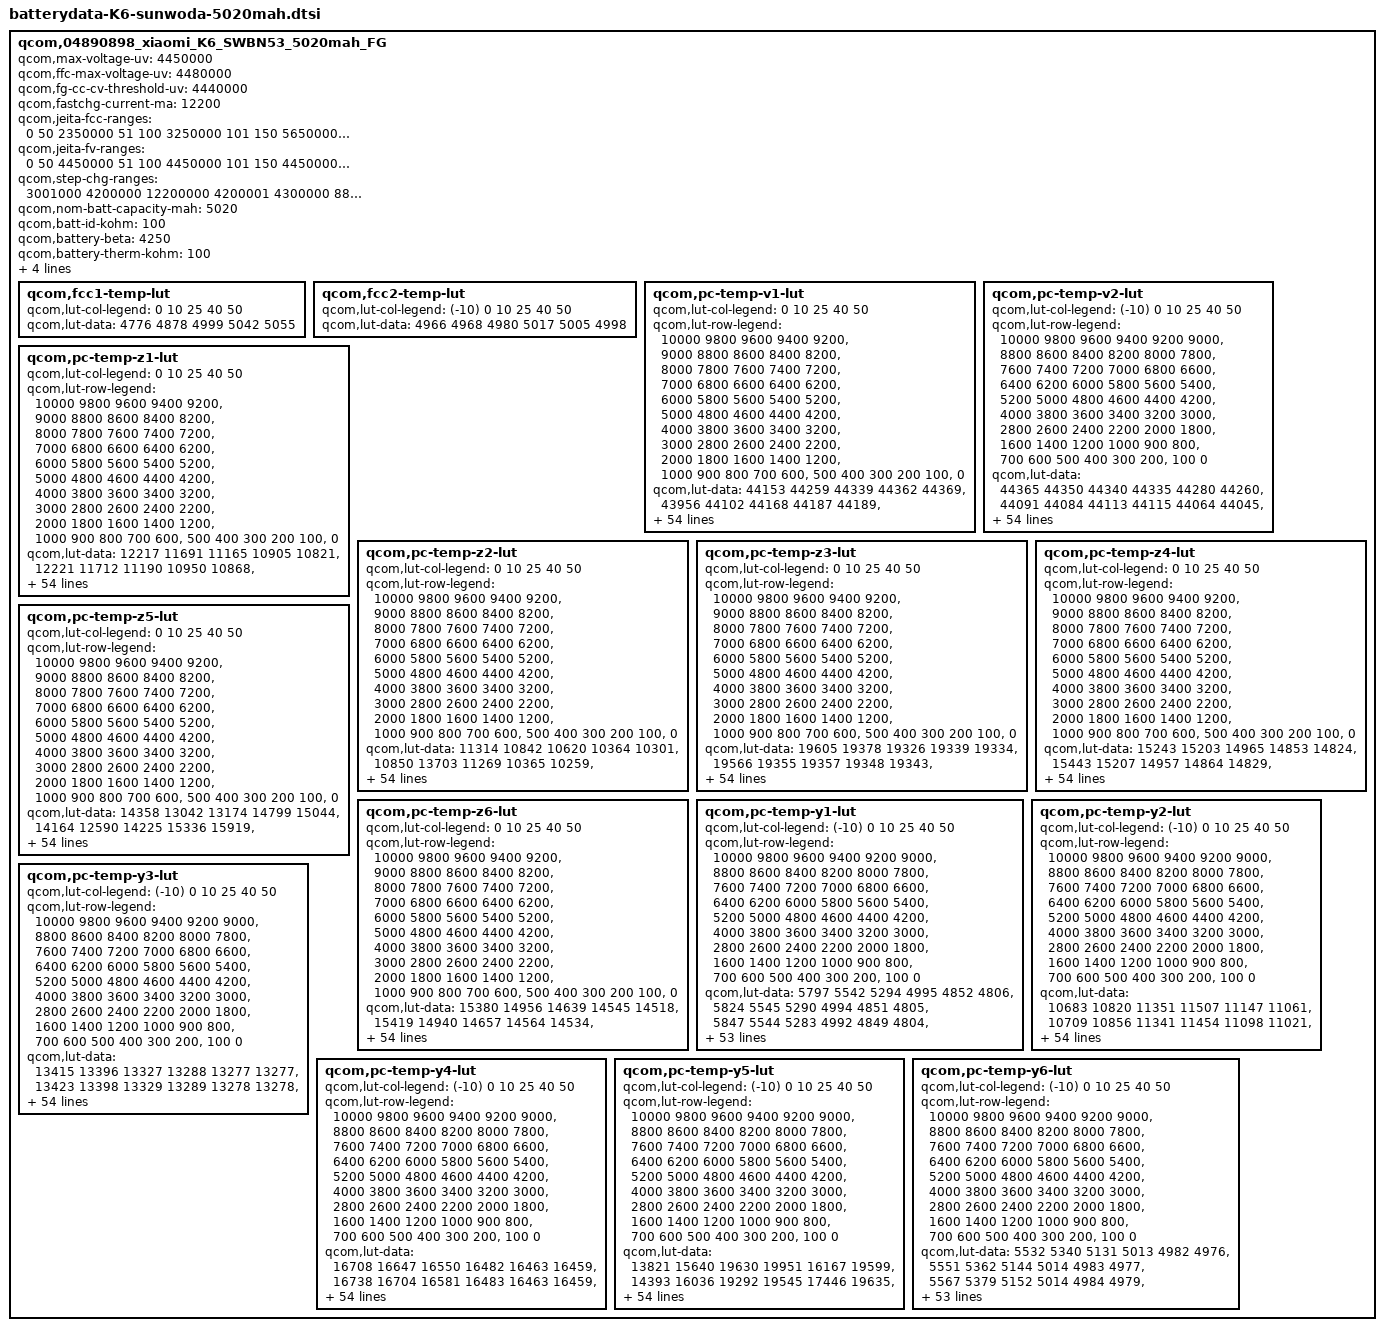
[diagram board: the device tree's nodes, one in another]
/*
 * Copyright (c) 2019, The Linux Foundation. All rights reserved.
 *
 * This program is free software; you can redistribute it and/or modify
 * it under the terms of the GNU General Public License version 2 and
 * only version 2 as published by the Free Software Foundation.
 *
 * This program is distributed in the hope that it will be useful,
 * but WITHOUT ANY WARRANTY; without even the implied warranty of
 * MERCHANTABILITY or FITNESS FOR A PARTICULAR PURPOSE.  See the
 * GNU General Public License for more details.
 */

qcom,04890898_xiaomi_K6_SWBN53_5020mah_FG {
    	/* 04890898_xiaomi_K6_SWBN53_5020mah_FG_averaged_MasterSlave_Oct28th2020 */
	qcom,max-voltage-uv = <4450000>;
	qcom,ffc-max-voltage-uv = <4480000>;
	qcom,fg-cc-cv-threshold-uv = <4440000>;
	qcom,fastchg-current-ma = <12200>;
	qcom,jeita-fcc-ranges = <0   50   2350000
				51  100  3250000
				101 150  5650000
				151 480  12200000
				481 600  2400000>;
	qcom,jeita-fv-ranges = <0   50  4450000
				51  100  4450000
				101 150  4450000
				151 480  4480000
				481 600  4100000>;
	qcom,step-chg-ranges = <3001000  4200000  12200000
				4200001  4300000  8800000
				4300001  4400000  7300000
				4400001  4470000  5800000
				4470001  4480000  5800000>;
	qcom,nom-batt-capacity-mah = <5020>;
	qcom,batt-id-kohm = <100>;
	qcom,battery-beta = <4250>;
	qcom,battery-therm-kohm = <100>;
	qcom,battery-type = "K6_sunwoda_5020mah";
	qcom,qg-batt-profile-ver = <100>;
	//mi,six-pin-battery;
	mi,use-bq-pump;
	mi,step-chg-hysteresis = <5000>;

	qcom,fcc1-temp-lut {
		qcom,lut-col-legend = <0 10 25 40 50>;
		qcom,lut-data = <4776 4878 4999 5042 5055>;
	};

	qcom,fcc2-temp-lut {
		qcom,lut-col-legend = <(-10) 0 10 25 40 50>;
		qcom,lut-data = <4966 4968 4980 5017 5005 4998>;
	};

	qcom,pc-temp-v1-lut {
		qcom,lut-col-legend = <0 10 25 40 50>;
		qcom,lut-row-legend = <10000 9800 9600 9400 9200>,
			<9000 8800 8600 8400 8200>,
			<8000 7800 7600 7400 7200>,
			<7000 6800 6600 6400 6200>,
			<6000 5800 5600 5400 5200>,
			<5000 4800 4600 4400 4200>,
			<4000 3800 3600 3400 3200>,
			<3000 2800 2600 2400 2200>,
			<2000 1800 1600 1400 1200>,
			<1000 900 800 700 600>,
			<500 400 300 200 100>,
			<0>;
		qcom,lut-data = <44153 44259 44339 44362 44369>,
			<43956 44102 44168 44187 44189>,
			<43747 43908 43984 44002 44006>,
			<43529 43687 43788 43810 43816>,
			<43300 43462 43580 43608 43617>,
			<43065 43231 43359 43396 43409>,
			<42826 42996 43121 43171 43186>,
			<42584 42759 42876 42934 42948>,
			<42342 42520 42631 42693 42707>,
			<42104 42279 42384 42447 42462>,
			<41870 42034 42141 42200 42216>,
			<41641 41791 41901 41957 41975>,
			<41417 41557 41664 41714 41736>,
			<41200 41329 41429 41476 41500>,
			<40990 41113 41197 41244 41267>,
			<40788 40917 40974 41019 41040>,
			<40586 40728 40763 40805 40821>,
			<40378 40530 40560 40600 40609>,
			<40174 40327 40368 40403 40408>,
			<39984 40117 40188 40220 40227>,
			<39815 39889 39984 40025 40039>,
			<39640 39643 39704 39773 39796>,
			<39422 39417 39417 39489 39514>,
			<39180 39206 39224 39275 39291>,
			<38993 39028 39081 39121 39126>,
			<38861 38904 38954 38987 38985>,
			<38755 38808 38835 38854 38856>,
			<38670 38720 38727 38729 38741>,
			<38599 38632 38623 38619 38632>,
			<38536 38550 38522 38522 38530>,
			<38477 38474 38432 38434 38435>,
			<38423 38402 38355 38351 38347>,
			<38374 38337 38285 38274 38265>,
			<38330 38282 38222 38202 38189>,
			<38289 38234 38167 38135 38118>,
			<38251 38188 38113 38070 38046>,
			<38214 38150 38063 38007 37971>,
			<38167 38105 38010 37944 37892>,
			<38094 38031 37938 37862 37800>,
			<37998 37929 37839 37757 37690>,
			<37889 37816 37726 37638 37569>,
			<37752 37687 37600 37509 37436>,
			<37600 37542 37458 37369 37292>,
			<37428 37367 37290 37208 37133>,
			<37288 37227 37159 37089 37015>,
			<37224 37147 37083 37017 36953>,
			<37189 37120 37065 36996 36934>,
			<37162 37101 37045 36981 36915>,
			<37126 37077 37017 36942 36867>,
			<37018 36974 36867 36754 36655>,
			<36672 36639 36494 36377 36275>,
			<36182 36163 36006 35886 35783>,
			<35556 35553 35374 35252 35147>,
			<34698 34721 34506 34372 34265>,
			<33313 33404 33107 32955 32841>,
			<30000 30000 30000 30000 30000>;
	};

	qcom,pc-temp-v2-lut {
		qcom,lut-col-legend = <(-10) 0 10 25 40 50>;
		qcom,lut-row-legend = <10000 9800 9600 9400 9200 9000>,
			<8800 8600 8400 8200 8000 7800>,
			<7600 7400 7200 7000 6800 6600>,
			<6400 6200 6000 5800 5600 5400>,
			<5200 5000 4800 4600 4400 4200>,
			<4000 3800 3600 3400 3200 3000>,
			<2800 2600 2400 2200 2000 1800>,
			<1600 1400 1200 1000 900 800>,
			<700 600 500 400 300 200>,
			<100 0>;
		qcom,lut-data = <44365 44350 44340 44335 44280 44260>,
			<44091 44084 44113 44115 44064 44045>,
			<43836 43832 43889 43898 43850 43831>,
			<43606 43599 43672 43685 43638 43621>,
			<43401 43386 43464 43478 43431 43413>,
			<43190 43167 43248 43263 43216 43199>,
			<42953 42926 43011 43029 42984 42969>,
			<42704 42674 42766 42786 42742 42730>,
			<42454 42422 42520 42541 42499 42489>,
			<42199 42168 42273 42293 42253 42244>,
			<41953 41920 42028 42046 42009 41999>,
			<41731 41683 41787 41803 41767 41758>,
			<41520 41454 41549 41562 41529 41520>,
			<41291 41228 41315 41327 41295 41287>,
			<41040 41008 41086 41098 41068 41058>,
			<40780 40791 40863 40874 40847 40836>,
			<40516 40580 40655 40658 40632 40624>,
			<40247 40370 40452 40448 40423 40419>,
			<39988 40134 40227 40243 40223 40221>,
			<39732 39850 39970 40047 40035 40035>,
			<39492 39571 39713 39835 39834 39835>,
			<39284 39336 39473 39571 39578 39583>,
			<39096 39125 39246 39294 39302 39309>,
			<38920 38936 39053 39084 39091 39097>,
			<38754 38767 38888 38917 38924 38933>,
			<38597 38612 38740 38771 38780 38789>,
			<38438 38465 38607 38640 38650 38659>,
			<38283 38326 38486 38523 38534 38541>,
			<38169 38203 38375 38415 38428 38433>,
			<38089 38088 38272 38315 38330 38331>,
			<38025 37994 38177 38223 38240 38238>,
			<37966 37937 38085 38136 38160 38156>,
			<37914 37897 37998 38056 38085 38080>,
			<37860 37860 37920 37981 38005 37996>,
			<37806 37828 37851 37914 37920 37902>,
			<37750 37792 37790 37843 37829 37802>,
			<37686 37744 37738 37755 37726 37688>,
			<37617 37679 37693 37660 37615 37566>,
			<37539 37601 37634 37570 37513 37458>,
			<37450 37504 37553 37485 37421 37366>,
			<37353 37390 37452 37392 37326 37272>,
			<37255 37268 37332 37280 37215 37157>,
			<37155 37135 37190 37156 37094 37030>,
			<37063 37017 37053 37016 36957 36894>,
			<36976 36913 36942 36927 36873 36813>,
			<36885 36816 36875 36889 36844 36787>,
			<36833 36752 36843 36873 36832 36774>,
			<36768 36676 36809 36850 36809 36750>,
			<36678 36565 36744 36792 36741 36659>,
			<36518 36406 36589 36581 36480 36377>,
			<36230 36128 36251 36150 36040 35920>,
			<35778 35700 35732 35586 35470 35345>,
			<35131 35080 35027 34844 34723 34586>,
			<34161 34182 34058 33789 33664 33532>,
			<32544 32618 32490 32094 32024 31689>,
			<26757 28288 28401 26924 26615 26574>;
	};

	qcom,pc-temp-z1-lut {
		qcom,lut-col-legend = <0 10 25 40 50>;
		qcom,lut-row-legend = <10000 9800 9600 9400 9200>,
			<9000 8800 8600 8400 8200>,
			<8000 7800 7600 7400 7200>,
			<7000 6800 6600 6400 6200>,
			<6000 5800 5600 5400 5200>,
			<5000 4800 4600 4400 4200>,
			<4000 3800 3600 3400 3200>,
			<3000 2800 2600 2400 2200>,
			<2000 1800 1600 1400 1200>,
			<1000 900 800 700 600>,
			<500 400 300 200 100>,
			<0>;
		qcom,lut-data = <12217 11691 11165 10905 10821>,
			<12221 11712 11190 10950 10868>,
			<12230 11721 11205 10962 10881>,
			<12232 11727 11204 10965 10884>,
			<12320 11724 11197 10962 10884>,
			<12454 11707 11191 10958 10882>,
			<12465 11687 11182 10954 10880>,
			<12322 11671 11173 10948 10878>,
			<12195 11656 11166 10945 10876>,
			<12172 11643 11160 10943 10875>,
			<12155 11632 11157 10942 10874>,
			<12140 11624 11155 10941 10874>,
			<12120 11621 11155 10940 10873>,
			<12101 11618 11153 10939 10873>,
			<12091 11616 11151 10939 10873>,
			<12083 11611 11150 10939 10874>,
			<12079 11606 11150 10939 10874>,
			<12074 11604 11151 10940 10876>,
			<12066 11602 11152 10941 10877>,
			<12063 11600 11153 10942 10879>,
			<12062 11601 11154 10943 10881>,
			<12061 11603 11154 10944 10882>,
			<12065 11606 11154 10944 10882>,
			<12072 11610 11155 10944 10883>,
			<12075 11614 11157 10946 10884>,
			<12078 11619 11160 10949 10886>,
			<12083 11626 11163 10951 10888>,
			<12084 11630 11166 10954 10891>,
			<12080 11626 11170 10957 10893>,
			<12078 11621 11174 10960 10896>,
			<12084 11621 11179 10963 10899>,
			<12092 11626 11183 10967 10902>,
			<12096 11632 11188 10970 10905>,
			<12102 11639 11193 10974 10909>,
			<12106 11647 11198 10979 10913>,
			<12108 11655 11203 10983 10917>,
			<12116 11662 11208 10987 10920>,
			<12122 11669 11214 10991 10923>,
			<12129 11679 11218 10995 10926>,
			<12139 11690 11223 10999 10929>,
			<12158 11696 11228 11002 10932>,
			<12198 11698 11237 11005 10935>,
			<12205 11704 11243 11007 10937>,
			<12168 11738 11245 11010 10939>,
			<12191 11741 11254 11014 10941>,
			<12190 11725 11260 11017 10942>,
			<12209 11725 11258 11016 10942>,
			<12196 11726 11260 11018 10944>,
			<12207 11736 11264 11023 10947>,
			<12207 11741 11271 11025 10950>,
			<12207 11742 11279 11029 10954>,
			<12214 11751 11285 11036 10960>,
			<12220 11776 11293 11043 10968>,
			<12266 11945 11310 11054 10977>,
			<12266 11945 11310 11054 10977>,
			<12266 11945 11310 11054 10977>;
	};

	qcom,pc-temp-z2-lut {
		qcom,lut-col-legend = <0 10 25 40 50>;
		qcom,lut-row-legend = <10000 9800 9600 9400 9200>,
			<9000 8800 8600 8400 8200>,
			<8000 7800 7600 7400 7200>,
			<7000 6800 6600 6400 6200>,
			<6000 5800 5600 5400 5200>,
			<5000 4800 4600 4400 4200>,
			<4000 3800 3600 3400 3200>,
			<3000 2800 2600 2400 2200>,
			<2000 1800 1600 1400 1200>,
			<1000 900 800 700 600>,
			<500 400 300 200 100>,
			<0>;
		qcom,lut-data = <11314 10842 10620 10364 10301>,
			<10850 13703 11269 10365 10259>,
			<10646 13021 11622 10394 10271>,
			<10562 11330 11590 10407 10275>,
			<10524 10654 11353 10415 10260>,
			<10497 10599 11098 10433 10239>,
			<10466 10574 10805 10584 10222>,
			<10434 10634 10570 10923 10207>,
			<10411 10826 10595 11006 10200>,
			<10399 10921 10800 10632 10157>,
			<10392 10758 10906 10268 10108>,
			<10390 10538 11072 10219 10109>,
			<10396 10501 11282 10196 10130>,
			<10405 10525 11195 10192 10146>,
			<10421 10587 10772 10228 10154>,
			<10451 11968 10556 10292 10163>,
			<10478 13823 10940 10512 10180>,
			<10498 13798 11480 10927 10204>,
			<10515 11966 11663 11139 10223>,
			<10522 10668 11754 11236 10234>,
			<10526 10643 11781 11294 10248>,
			<10528 10641 11390 11146 10293>,
			<10529 10641 10848 10778 10395>,
			<10529 10629 10708 10608 10515>,
			<10529 10614 10661 10493 10736>,
			<10527 10618 10646 10416 10907>,
			<10526 10641 10689 10476 10798>,
			<10527 10661 10747 10604 10495>,
			<10535 10674 10754 10629 10302>,
			<10544 10683 10740 10511 10190>,
			<10552 10683 10721 10378 10130>,
			<10562 10676 10677 10296 10128>,
			<10570 10671 10629 10231 10136>,
			<10577 10674 10625 10221 10150>,
			<10584 10681 10644 10255 10192>,
			<10593 10688 10670 10305 10247>,
			<10603 10696 10708 10366 10309>,
			<10616 10708 10754 10446 10377>,
			<10639 10733 10792 10535 10429>,
			<10668 10771 10827 10655 10476>,
			<10691 10792 10850 10725 10500>,
			<10709 10798 10858 10714 10484>,
			<10742 10809 10865 10695 10453>,
			<10820 10852 10873 10671 10429>,
			<11215 11072 10903 10592 10410>,
			<11037 11156 10909 10540 10398>,
			<10956 11147 10845 10525 10421>,
			<10937 11187 10867 10543 10432>,
			<10969 11413 10897 10641 10540>,
			<10946 11531 10947 10576 10502>,
			<10828 11628 10814 10336 10225>,
			<10659 11691 10704 10284 10164>,
			<10473 11569 10641 10239 10117>,
			<10270 11359 10687 10174 10033>,
			<10270 11359 10687 10174 10033>,
			<10270 11359 10687 10174 10033>;
	};

	qcom,pc-temp-z3-lut {
		qcom,lut-col-legend = <0 10 25 40 50>;
		qcom,lut-row-legend = <10000 9800 9600 9400 9200>,
			<9000 8800 8600 8400 8200>,
			<8000 7800 7600 7400 7200>,
			<7000 6800 6600 6400 6200>,
			<6000 5800 5600 5400 5200>,
			<5000 4800 4600 4400 4200>,
			<4000 3800 3600 3400 3200>,
			<3000 2800 2600 2400 2200>,
			<2000 1800 1600 1400 1200>,
			<1000 900 800 700 600>,
			<500 400 300 200 100>,
			<0>;
		qcom,lut-data = <19605 19378 19326 19339 19334>,
			<19566 19355 19357 19348 19343>,
			<19623 19402 19385 19369 19359>,
			<19662 19499 19410 19385 19372>,
			<19677 19542 19436 19393 19379>,
			<19688 19546 19449 19401 19385>,
			<19694 19550 19451 19412 19392>,
			<19700 19560 19453 19425 19398>,
			<19702 19580 19458 19429 19400>,
			<19702 19590 19470 19414 19397>,
			<19700 19575 19475 19397 19393>,
			<19699 19550 19477 19393 19389>,
			<19694 19536 19477 19391 19385>,
			<19689 19528 19463 19389 19382>,
			<19682 19519 19432 19387 19380>,
			<19673 19482 19417 19385 19378>,
			<19665 19440 19431 19385 19375>,
			<19656 19442 19449 19388 19372>,
			<19648 19473 19450 19387 19368>,
			<19647 19498 19444 19382 19360>,
			<19652 19513 19438 19376 19354>,
			<19659 19535 19434 19376 19355>,
			<19671 19543 19429 19378 19361>,
			<19688 19533 19418 19375 19370>,
			<19695 19520 19396 19361 19390>,
			<19690 19510 19384 19350 19407>,
			<19682 19501 19387 19370 19408>,
			<19675 19498 19394 19412 19407>,
			<19667 19501 19406 19423 19405>,
			<19660 19508 19428 19415 19398>,
			<19655 19514 19440 19404 19390>,
			<19651 19520 19437 19396 19384>,
			<19647 19524 19432 19390 19379>,
			<19644 19523 19427 19383 19372>,
			<19641 19520 19420 19375 19360>,
			<19638 19517 19414 19369 19352>,
			<19636 19513 19409 19364 19351>,
			<19633 19509 19406 19360 19351>,
			<19627 19506 19402 19359 19350>,
			<19619 19502 19400 19360 19351>,
			<19612 19498 19398 19361 19352>,
			<19604 19493 19397 19366 19357>,
			<19592 19486 19396 19370 19362>,
			<19569 19477 19395 19370 19363>,
			<19507 19444 19382 19360 19360>,
			<19315 19423 19372 19346 19346>,
			<19303 19422 19361 19344 19334>,
			<19294 19408 19362 19334 19329>,
			<19291 19358 19347 19326 19323>,
			<19292 19350 19356 19344 19336>,
			<19299 19316 19365 19363 19354>,
			<19295 19310 19364 19364 19356>,
			<19297 19302 19364 19356 19351>,
			<19303 19299 19341 19358 19355>,
			<19303 19299 19341 19358 19355>,
			<19303 19299 19341 19358 19355>;
	};

	qcom,pc-temp-z4-lut {
		qcom,lut-col-legend = <0 10 25 40 50>;
		qcom,lut-row-legend = <10000 9800 9600 9400 9200>,
			<9000 8800 8600 8400 8200>,
			<8000 7800 7600 7400 7200>,
			<7000 6800 6600 6400 6200>,
			<6000 5800 5600 5400 5200>,
			<5000 4800 4600 4400 4200>,
			<4000 3800 3600 3400 3200>,
			<3000 2800 2600 2400 2200>,
			<2000 1800 1600 1400 1200>,
			<1000 900 800 700 600>,
			<500 400 300 200 100>,
			<0>;
		qcom,lut-data = <15243 15203 14965 14853 14824>,
			<15443 15207 14957 14864 14829>,
			<15409 15176 14942 14855 14824>,
			<15361 15106 14916 14842 14817>,
			<15270 15042 14868 14822 14801>,
			<15166 14989 14832 14797 14780>,
			<15092 14938 14812 14767 14762>,
			<15031 14875 14795 14731 14745>,
			<14980 14803 14768 14716 14732>,
			<14937 14773 14727 14720 14722>,
			<14902 14776 14701 14724 14714>,
			<14873 14780 14681 14720 14709>,
			<14849 14778 14663 14715 14706>,
			<14829 14766 14669 14709 14702>,
			<14808 14756 14698 14704 14697>,
			<14788 14778 14713 14697 14692>,
			<14780 14807 14683 14684 14688>,
			<14786 14800 14644 14667 14685>,
			<14794 14762 14639 14660 14682>,
			<14793 14743 14640 14658 14679>,
			<14777 14753 14641 14657 14677>,
			<14765 14763 14697 14687 14699>,
			<14778 14778 14780 14756 14756>,
			<14813 14821 14815 14790 14775>,
			<14834 14857 14836 14804 14753>,
			<14842 14859 14843 14810 14726>,
			<14847 14852 14832 14783 14712>,
			<14846 14842 14810 14725 14702>,
			<14837 14826 14785 14704 14696>,
			<14827 14805 14751 14700 14692>,
			<14817 14787 14729 14698 14689>,
			<14806 14772 14721 14695 14685>,
			<14796 14761 14716 14691 14680>,
			<14788 14756 14714 14691 14678>,
			<14780 14752 14712 14691 14679>,
			<14773 14749 14712 14691 14680>,
			<14766 14745 14712 14691 14680>,
			<14760 14742 14713 14691 14680>,
			<14756 14743 14715 14693 14682>,
			<14752 14744 14723 14702 14691>,
			<14746 14744 14728 14709 14697>,
			<14736 14733 14721 14702 14693>,
			<14726 14721 14711 14694 14688>,
			<14718 14712 14707 14695 14689>,
			<14697 14683 14690 14688 14677>,
			<14860 14670 14669 14670 14660>,
			<14869 14663 14665 14660 14657>,
			<14871 14667 14649 14650 14642>,
			<14868 14714 14651 14641 14631>,
			<14865 14723 14654 14647 14652>,
			<14870 14777 14667 14652 14657>,
			<14879 14786 14671 14655 14659>,
			<14886 14799 14673 14664 14666>,
			<14891 14806 14700 14663 14662>,
			<14891 14806 14700 14663 14662>,
			<14891 14806 14700 14663 14662>;
	};

	qcom,pc-temp-z5-lut {
		qcom,lut-col-legend = <0 10 25 40 50>;
		qcom,lut-row-legend = <10000 9800 9600 9400 9200>,
			<9000 8800 8600 8400 8200>,
			<8000 7800 7600 7400 7200>,
			<7000 6800 6600 6400 6200>,
			<6000 5800 5600 5400 5200>,
			<5000 4800 4600 4400 4200>,
			<4000 3800 3600 3400 3200>,
			<3000 2800 2600 2400 2200>,
			<2000 1800 1600 1400 1200>,
			<1000 900 800 700 600>,
			<500 400 300 200 100>,
			<0>;
		qcom,lut-data = <14358 13042 13174 14799 15044>,
			<14164 12590 14225 15336 15919>,
			<15320 13713 15286 17048 17568>,
			<16177 16338 16360 18355 18930>,
			<16544 17771 17616 19017 19745>,
			<16877 18096 18605 19700 20486>,
			<17321 18407 19159 21411 21591>,
			<17943 19477 19725 24101 23047>,
			<18647 21748 21729 24894 24024>,
			<19374 22939 26370 23063 24668>,
			<20161 22585 28894 21311 25096>,
			<20977 22002 31296 21370 25064>,
			<21812 22033 33783 21840 24858>,
			<22709 22749 31868 22418 24797>,
			<23875 23393 25439 23255 25630>,
			<25236 22295 22278 24230 26875>,
			<25897 21100 30543 26677 27906>,
			<25910 21505 41203 30900 28916>,
			<25866 22342 42609 32258 29192>,
			<26237 23800 42344 32463 28152>,
			<28185 30288 41895 32746 26960>,
			<31273 42506 40002 31744 26603>,
			<37948 47069 36541 28646 26393>,
			<48221 41039 31426 25570 26246>,
			<52119 32878 23107 20159 25738>,
			<48330 28592 18786 16252 25286>,
			<42732 25303 18518 19274 25520>,
			<39305 24132 18384 25765 26213>,
			<36519 24617 19235 27556 26725>,
			<35052 25687 23311 26834 27004>,
			<34935 27459 26938 26246 27324>,
			<35131 31009 28884 26481 28151>,
			<35495 34195 30359 26992 29305>,
			<36183 36217 31371 27213 29416>,
			<37086 37796 32198 27299 27395>,
			<38162 38512 32539 27338 25709>,
			<39513 38911 32479 27307 26604>,
			<40603 39114 32324 27203 28480>,
			<41458 39085 31755 26945 28749>,
			<42093 38892 29800 26140 26785>,
			<42161 38542 28359 25586 25249>,
			<41800 37479 27946 26263 26560>,
			<41052 36367 27733 27084 28415>,
			<38846 35410 27565 26853 28650>,
			<34185 36237 27021 24518 28713>,
			<13282 32634 27317 21940 23606>,
			<12868 32053 24217 22646 20328>,
			<12599 28592 27343 22129 22395>,
			<12554 19252 22954 23464 26381>,
			<12644 17563 24085 29261 28352>,
			<12820 13714 21021 26234 25155>,
			<12557 13313 19734 24012 23062>,
			<12430 12834 18965 19294 19072>,
			<12355 12596 15023 18255 18082>,
			<12355 12596 15023 18255 18082>,
			<12355 12596 15023 18255 18082>;
	};

	qcom,pc-temp-z6-lut {
		qcom,lut-col-legend = <0 10 25 40 50>;
		qcom,lut-row-legend = <10000 9800 9600 9400 9200>,
			<9000 8800 8600 8400 8200>,
			<8000 7800 7600 7400 7200>,
			<7000 6800 6600 6400 6200>,
			<6000 5800 5600 5400 5200>,
			<5000 4800 4600 4400 4200>,
			<4000 3800 3600 3400 3200>,
			<3000 2800 2600 2400 2200>,
			<2000 1800 1600 1400 1200>,
			<1000 900 800 700 600>,
			<500 400 300 200 100>,
			<0>;
		qcom,lut-data = <15380 14956 14639 14545 14518>,
			<15419 14940 14657 14564 14534>,
			<15400 14939 14667 14574 14543>,
			<15374 14940 14666 14576 14546>,
			<15323 14936 14657 14571 14543>,
			<15262 14908 14647 14565 14539>,
			<15216 14872 14638 14559 14535>,
			<15175 14845 14629 14552 14531>,
			<15140 14820 14619 14546 14527>,
			<15110 14801 14608 14538 14521>,
			<15083 14786 14598 14531 14515>,
			<15060 14773 14589 14526 14510>,
			<15040 14762 14582 14523 14506>,
			<15022 14751 14577 14519 14503>,
			<15003 14742 14573 14515 14500>,
			<14984 14732 14568 14511 14496>,
			<14973 14724 14563 14506 14493>,
			<14970 14722 14559 14501 14490>,
			<14968 14722 14555 14497 14486>,
			<14967 14723 14552 14493 14481>,
			<14965 14731 14551 14490 14476>,
			<14964 14749 14575 14504 14487>,
			<14975 14763 14607 14535 14515>,
			<15001 14776 14611 14544 14526>,
			<15014 14785 14610 14543 14526>,
			<15016 14784 14609 14542 14526>,
			<15017 14777 14606 14541 14524>,
			<15014 14771 14601 14539 14519>,
			<15007 14766 14598 14536 14515>,
			<15000 14762 14595 14531 14510>,
			<14994 14759 14592 14525 14506>,
			<14989 14756 14589 14520 14501>,
			<14985 14755 14585 14516 14497>,
			<14982 14754 14582 14512 14492>,
			<14980 14753 14579 14509 14487>,
			<14979 14752 14576 14506 14483>,
			<14979 14751 14575 14503 14482>,
			<14979 14750 14574 14501 14482>,
			<14981 14751 14574 14502 14482>,
			<14983 14754 14577 14507 14486>,
			<14984 14754 14579 14510 14490>,
			<14984 14751 14577 14510 14491>,
			<14982 14747 14573 14509 14491>,
			<14979 14744 14572 14510 14493>,
			<14948 14724 14560 14502 14487>,
			<14929 14709 14546 14488 14472>,
			<14926 14706 14539 14482 14465>,
			<14925 14703 14534 14473 14456>,
			<14927 14701 14528 14465 14447>,
			<14933 14705 14535 14477 14463>,
			<14945 14715 14547 14492 14478>,
			<14952 14721 14551 14496 14482>,
			<14965 14728 14555 14498 14485>,
			<14985 14738 14559 14501 14489>,
			<14985 14738 14559 14501 14489>,
			<14985 14738 14559 14501 14489>;
	};

	qcom,pc-temp-y1-lut {
		qcom,lut-col-legend = <(-10) 0 10 25 40 50>;
		qcom,lut-row-legend = <10000 9800 9600 9400 9200 9000>,
			<8800 8600 8400 8200 8000 7800>,
			<7600 7400 7200 7000 6800 6600>,
			<6400 6200 6000 5800 5600 5400>,
			<5200 5000 4800 4600 4400 4200>,
			<4000 3800 3600 3400 3200 3000>,
			<2800 2600 2400 2200 2000 1800>,
			<1600 1400 1200 1000 900 800>,
			<700 600 500 400 300 200>,
			<100 0>;
		qcom,lut-data = <5797 5542 5294 4995 4852 4806>,
			<5824 5545 5290 4994 4851 4805>,
			<5847 5544 5283 4992 4849 4804>,
			<5865 5541 5276 4989 4848 4803>,
			<5877 5536 5270 4985 4846 4801>,
			<5881 5531 5266 4983 4845 4800>,
			<5875 5525 5265 4981 4843 4800>,
			<5865 5518 5263 4979 4842 4799>,
			<5862 5516 5262 4977 4840 4798>,
			<5860 5520 5257 4975 4839 4797>,
			<5859 5523 5253 4973 4838 4796>,
			<5863 5523 5256 4971 4837 4795>,
			<5869 5521 5260 4968 4837 4794>,
			<5873 5534 5260 4967 4836 4794>,
			<5876 5639 5252 4966 4835 4793>,
			<5880 5727 5245 4965 4835 4793>,
			<5970 5681 5244 4965 4835 4794>,
			<6154 5575 5244 4965 4835 4794>,
			<6198 5540 5244 4965 4835 4795>,
			<6027 5536 5246 4965 4836 4795>,
			<5869 5534 5248 4966 4836 4795>,
			<5863 5535 5249 4968 4837 4796>,
			<5865 5539 5251 4970 4838 4798>,
			<5867 5540 5253 4972 4839 4799>,
			<5868 5537 5255 4974 4841 4800>,
			<5867 5534 5256 4976 4842 4800>,
			<5862 5534 5256 4977 4843 4801>,
			<5850 5534 5255 4979 4844 4803>,
			<5845 5533 5254 4981 4846 4804>,
			<5846 5536 5257 4983 4848 4806>,
			<5848 5538 5260 4985 4850 4808>,
			<5849 5536 5261 4988 4852 4809>,
			<5848 5531 5262 4991 4854 4811>,
			<5849 5529 5264 4994 4856 4813>,
			<5851 5527 5266 4996 4858 4814>,
			<5853 5526 5268 4998 4860 4816>,
			<5851 5524 5268 4999 4862 4817>,
			<5840 5520 5268 5001 4863 4819>,
			<5831 5518 5269 5003 4864 4820>,
			<5824 5519 5270 5006 4865 4821>,
			<5817 5520 5273 5009 4866 4822>,
			<5814 5517 5278 5010 4868 4824>,
			<5816 5505 5285 5012 4869 4825>,
			<5811 5504 5288 5017 4873 4829>,
			<5805 5508 5293 5023 4876 4830>,
			<5842 5520 5295 5026 4877 4830>,
			<5867 5538 5303 5029 4877 4831>,
			<5871 5541 5302 5029 4877 4831>,
			<5853 5544 5308 5029 4876 4832>,
			<5852 5542 5306 5028 4878 4833>,
			<5853 5536 5315 5032 4883 4835>,
			<5868 5537 5312 5043 4884 4837>,
			<5902 5540 5316 5045 4888 4842>,
			<5928 5557 5320 5060 4896 4849>,
			<5928 5557 5320 5060 4896 4849>,
			<5928 5557 5320 5060 4896 4849>;
	};

	qcom,pc-temp-y2-lut {
		qcom,lut-col-legend = <(-10) 0 10 25 40 50>;
		qcom,lut-row-legend = <10000 9800 9600 9400 9200 9000>,
			<8800 8600 8400 8200 8000 7800>,
			<7600 7400 7200 7000 6800 6600>,
			<6400 6200 6000 5800 5600 5400>,
			<5200 5000 4800 4600 4400 4200>,
			<4000 3800 3600 3400 3200 3000>,
			<2800 2600 2400 2200 2000 1800>,
			<1600 1400 1200 1000 900 800>,
			<700 600 500 400 300 200>,
			<100 0>;
		qcom,lut-data = <10683 10820 11351 11507 11147 11061>,
			<10709 10856 11341 11454 11098 11021>,
			<10767 10914 11326 11395 11042 10983>,
			<10835 10976 11308 11337 10988 10947>,
			<10893 11027 11288 11287 10942 10914>,
			<10919 11049 11269 11253 10912 10883>,
			<10919 11045 11245 11232 10898 10855>,
			<10918 11038 11221 11215 10888 10830>,
			<10920 11037 11208 11197 10869 10810>,
			<10936 11042 11198 11176 10835 10795>,
			<10949 11045 11194 11163 10815 10783>,
			<10940 11030 11202 11160 10818 10773>,
			<10922 11000 11223 11160 10826 10763>,
			<10937 11012 11245 11167 10845 10761>,
			<11110 11186 11270 11194 10909 10761>,
			<11257 11332 11302 11230 10952 10760>,
			<11219 11319 11373 11268 10946 10761>,
			<11130 11283 11465 11317 10936 10763>,
			<11106 11274 11489 11393 10957 10780>,
			<11159 11301 11484 11524 11107 10865>,
			<11219 11333 11478 11599 11214 10959>,
			<11248 11353 11483 11561 11196 11027>,
			<11270 11371 11495 11501 11163 11085>,
			<11276 11380 11506 11490 11156 11108>,
			<11268 11383 11518 11503 11162 11107>,
			<11260 11382 11532 11522 11173 11105>,
			<11261 11360 11551 11548 11198 11115>,
			<11263 11314 11576 11580 11237 11129>,
			<11262 11297 11593 11607 11274 11150>,
			<11250 11343 11607 11630 11310 11188>,
			<11224 11393 11614 11654 11354 11227>,
			<11072 11372 11611 11687 11439 11262>,
			<10658 11282 11598 11718 11540 11295>,
			<10378 11192 11585 11723 11570 11306>,
			<10071 11124 11573 11719 11538 11308>,
			<9772 11044 11558 11712 11503 11307>,
			<9715 10862 11530 11670 11471 11294>,
			<9697 10504 11483 11604 11415 11264>,
			<9687 10267 11429 11577 11357 11235>,
			<9680 10008 11363 11566 11284 11195>,
			<9675 9738 11283 11553 11233 11160>,
			<9672 9687 11186 11529 11241 11149>,
			<9669 9676 11067 11492 11255 11139>,
			<9667 9670 10938 11437 11181 11053>,
			<9665 9666 10819 11324 11033 10905>,
			<9664 9664 10743 11268 10931 10829>,
			<9663 9664 10765 11258 10966 10822>,
			<9662 9662 10733 11266 11022 10831>,
			<9660 9661 10710 11275 11019 10849>,
			<9659 9660 10685 11254 10967 10821>,
			<9657 9659 10592 11201 10882 10767>,
			<9654 9657 10447 11106 10803 10700>,
			<9650 9656 9941 10985 10705 10601>,
			<9648 9653 9703 10883 10566 10418>,
			<9648 9653 9703 10883 10566 10418>,
			<9648 9653 9703 10883 10566 10418>;
	};

	qcom,pc-temp-y3-lut {
		qcom,lut-col-legend = <(-10) 0 10 25 40 50>;
		qcom,lut-row-legend = <10000 9800 9600 9400 9200 9000>,
			<8800 8600 8400 8200 8000 7800>,
			<7600 7400 7200 7000 6800 6600>,
			<6400 6200 6000 5800 5600 5400>,
			<5200 5000 4800 4600 4400 4200>,
			<4000 3800 3600 3400 3200 3000>,
			<2800 2600 2400 2200 2000 1800>,
			<1600 1400 1200 1000 900 800>,
			<700 600 500 400 300 200>,
			<100 0>;
		qcom,lut-data = <13415 13396 13327 13288 13277 13277>,
			<13423 13398 13329 13289 13278 13278>,
			<13433 13400 13330 13290 13280 13279>,
			<13444 13402 13332 13291 13282 13280>,
			<13453 13404 13333 13292 13283 13281>,
			<13457 13405 13335 13293 13284 13282>,
			<13456 13405 13335 13294 13284 13282>,
			<13454 13406 13336 13294 13285 13283>,
			<13453 13406 13337 13295 13285 13283>,
			<13453 13406 13339 13296 13286 13284>,
			<13452 13407 13340 13297 13287 13284>,
			<13460 13408 13340 13297 13287 13285>,
			<13476 13410 13340 13297 13288 13286>,
			<13477 13407 13339 13298 13289 13286>,
			<13445 13390 13337 13301 13292 13286>,
			<13418 13377 13333 13303 13294 13286>,
			<13419 13380 13332 13303 13293 13288>,
			<13422 13387 13331 13303 13292 13290>,
			<13422 13389 13330 13303 13292 13291>,
			<13413 13379 13328 13303 13294 13291>,
			<13403 13367 13326 13304 13295 13291>,
			<13397 13360 13323 13300 13292 13288>,
			<13393 13356 13319 13294 13285 13282>,
			<13388 13351 13316 13291 13282 13280>,
			<13384 13347 13314 13289 13281 13279>,
			<13378 13344 13313 13288 13280 13279>,
			<13367 13341 13313 13288 13280 13279>,
			<13348 13338 13312 13287 13279 13280>,
			<13338 13334 13312 13287 13279 13280>,
			<13335 13326 13311 13288 13280 13279>,
			<13334 13318 13310 13288 13280 13278>,
			<13336 13318 13309 13288 13280 13278>,
			<13341 13323 13309 13287 13281 13278>,
			<13348 13328 13308 13287 13281 13279>,
			<13363 13336 13307 13287 13281 13280>,
			<13383 13344 13307 13288 13281 13281>,
			<13403 13352 13308 13287 13281 13280>,
			<13425 13359 13311 13286 13280 13279>,
			<13448 13369 13313 13286 13280 13278>,
			<13475 13387 13316 13287 13281 13280>,
			<13505 13412 13318 13287 13282 13281>,
			<13540 13441 13320 13288 13283 13281>,
			<13583 13479 13322 13289 13284 13281>,
			<13638 13533 13324 13289 13282 13279>,
			<13709 13611 13329 13291 13282 13279>,
			<13788 13703 13338 13294 13288 13286>,
			<13772 13679 13338 13299 13291 13287>,
			<13844 13743 13347 13302 13293 13288>,
			<13944 13800 13358 13305 13292 13286>,
			<14073 13873 13365 13303 13288 13283>,
			<14280 13953 13369 13301 13286 13284>,
			<14740 14091 13378 13303 13288 13287>,
			<16468 14342 13411 13309 13294 13292>,
			<20884 14990 13540 13319 13301 13299>,
			<20884 14990 13540 13319 13301 13299>,
			<20884 14990 13540 13319 13301 13299>;
	};

	qcom,pc-temp-y4-lut {
		qcom,lut-col-legend = <(-10) 0 10 25 40 50>;
		qcom,lut-row-legend = <10000 9800 9600 9400 9200 9000>,
			<8800 8600 8400 8200 8000 7800>,
			<7600 7400 7200 7000 6800 6600>,
			<6400 6200 6000 5800 5600 5400>,
			<5200 5000 4800 4600 4400 4200>,
			<4000 3800 3600 3400 3200 3000>,
			<2800 2600 2400 2200 2000 1800>,
			<1600 1400 1200 1000 900 800>,
			<700 600 500 400 300 200>,
			<100 0>;
		qcom,lut-data = <16708 16647 16550 16482 16463 16459>,
			<16738 16704 16581 16483 16463 16459>,
			<16802 16782 16611 16484 16463 16460>,
			<16877 16861 16636 16485 16462 16460>,
			<16939 16923 16653 16486 16462 16461>,
			<16967 16950 16660 16487 16462 16461>,
			<16966 16944 16654 16488 16463 16461>,
			<16965 16931 16644 16489 16465 16461>,
			<16962 16920 16638 16490 16466 16462>,
			<16960 16908 16635 16492 16468 16462>,
			<16957 16900 16633 16495 16470 16463>,
			<16955 16901 16635 16501 16473 16465>,
			<16952 16904 16642 16508 16477 16467>,
			<16959 16915 16651 16514 16479 16469>,
			<17015 16979 16668 16518 16481 16474>,
			<17063 17031 16691 16525 16483 16478>,
			<17031 17021 16723 16539 16490 16483>,
			<16947 16990 16758 16558 16503 16487>,
			<16879 16950 16763 16579 16519 16497>,
			<16824 16873 16721 16605 16545 16520>,
			<16779 16794 16667 16618 16560 16535>,
			<16753 16750 16625 16580 16537 16519>,
			<16734 16716 16585 16515 16494 16485>,
			<16713 16690 16565 16492 16476 16471>,
			<16686 16669 16555 16484 16469 16465>,
			<16663 16649 16548 16480 16466 16462>,
			<16649 16622 16546 16482 16467 16462>,
			<16637 16590 16544 16487 16472 16464>,
			<16634 16570 16544 16492 16476 16466>,
			<16640 16558 16545 16497 16483 16472>,
			<16650 16550 16546 16503 16490 16480>,
			<16661 16552 16542 16509 16499 16489>,
			<16681 16564 16532 16516 16509 16499>,
			<16697 16578 16525 16520 16511 16502>,
			<16713 16593 16521 16523 16509 16500>,
			<16728 16611 16518 16525 16505 16497>,
			<16737 16635 16522 16511 16494 16489>,
			<16745 16667 16536 16488 16479 16478>,
			<16748 16687 16548 16481 16474 16476>,
			<16748 16700 16557 16480 16473 16479>,
			<16748 16710 16565 16480 16473 16482>,
			<16749 16708 16572 16483 16472 16480>,
			<16753 16700 16580 16486 16472 16476>,
			<16761 16703 16586 16478 16457 16456>,
			<16781 16725 16594 16480 16452 16449>,
			<16806 16770 16607 16489 16481 16494>,
			<16785 16764 16602 16506 16509 16526>,
			<16806 16811 16635 16532 16542 16559>,
			<16824 16859 16680 16562 16555 16555>,
			<16834 16906 16709 16536 16491 16492>,
			<16828 16926 16707 16496 16472 16471>,
			<16817 16927 16703 16502 16473 16470>,
			<17054 16924 16757 16519 16476 16471>,
			<18206 16987 16856 16560 16509 16513>,
			<18206 16987 16856 16560 16509 16513>,
			<18206 16987 16856 16560 16509 16513>;
	};

	qcom,pc-temp-y5-lut {
		qcom,lut-col-legend = <(-10) 0 10 25 40 50>;
		qcom,lut-row-legend = <10000 9800 9600 9400 9200 9000>,
			<8800 8600 8400 8200 8000 7800>,
			<7600 7400 7200 7000 6800 6600>,
			<6400 6200 6000 5800 5600 5400>,
			<5200 5000 4800 4600 4400 4200>,
			<4000 3800 3600 3400 3200 3000>,
			<2800 2600 2400 2200 2000 1800>,
			<1600 1400 1200 1000 900 800>,
			<700 600 500 400 300 200>,
			<100 0>;
		qcom,lut-data = <13821 15640 19630 19951 16167 19599>,
			<14393 16036 19292 19545 17446 19635>,
			<15310 16431 18894 19048 18223 19652>,
			<16314 16801 18497 18513 18624 19653>,
			<17145 17121 18164 17995 18773 19639>,
			<17544 17365 17958 17545 18793 19612>,
			<17570 17562 17872 17109 18228 19438>,
			<17548 17710 17814 16686 17233 19088>,
			<17513 17732 17730 16397 16788 18705>,
			<17437 17675 17612 16183 16604 18208>,
			<17383 17605 17442 15937 16417 17777>,
			<18484 17721 17099 15485 16066 17417>,
			<20615 17964 16587 15027 15713 17012>,
			<20941 17780 16095 14988 15757 16614>,
			<18550 16588 15515 15223 16427 16005>,
			<16533 15638 15169 15377 16898 15638>,
			<18247 17563 15518 15125 16268 15808>,
			<22070 21736 16495 14728 15198 16120>,
			<23191 22998 17735 14972 15031 16205>,
			<21959 22303 19834 16858 15601 16170>,
			<20823 21669 21417 18737 16413 16150>,
			<21037 21808 21717 19975 17678 16855>,
			<21710 22269 21872 20904 19085 18187>,
			<22045 22637 21927 20928 19321 18741>,
			<22167 22869 21903 20170 18788 18927>,
			<22234 23101 21917 19427 18115 18913>,
			<20728 23475 22156 18958 17320 18559>,
			<16512 23939 22576 18604 16479 17933>,
			<14337 23913 22871 18632 16281 17247>,
			<13801 19984 23106 19112 16317 16293>,
			<13500 15766 23372 19432 16391 15690>,
			<13419 15487 23962 19351 16607 15765>,
			<13312 15799 24849 19222 17051 16037>,
			<13286 16220 25015 19481 17656 16600>,
			<13414 17450 23477 21046 18731 18517>,
			<13583 18744 21896 22087 19805 20160>,
			<13722 18684 21589 22023 20679 20453>,
			<13923 17576 21461 21855 21479 20600>,
			<14012 16980 21240 21560 21839 20942>,
			<13901 16137 20624 20877 21959 21997>,
			<13695 15033 19824 20257 22125 23334>,
			<13451 14751 18995 19902 23343 24876>,
			<13156 14500 18128 19648 24757 26156>,
			<13134 14222 17610 19418 22056 21835>,
			<13211 13958 17383 18731 18454 17875>,
			<13258 13880 17394 18195 17877 16921>,
			<13327 14002 17498 18625 17679 16301>,
			<13461 14493 17938 18927 17332 15951>,
			<13926 15135 18830 19028 16902 15355>,
			<14277 16366 19500 19642 17574 16232>,
			<14178 16736 19282 21190 17281 16622>,
			<13647 15905 18071 20937 16977 16687>,
			<11789 14189 15316 21396 19300 19378>,
			<10005 12727 13780 22830 25054 25011>,
			<10005 12727 13780 22830 25054 25011>,
			<10005 12727 13780 22830 25054 25011>;
	};

	qcom,pc-temp-y6-lut {
		qcom,lut-col-legend = <(-10) 0 10 25 40 50>;
		qcom,lut-row-legend = <10000 9800 9600 9400 9200 9000>,
			<8800 8600 8400 8200 8000 7800>,
			<7600 7400 7200 7000 6800 6600>,
			<6400 6200 6000 5800 5600 5400>,
			<5200 5000 4800 4600 4400 4200>,
			<4000 3800 3600 3400 3200 3000>,
			<2800 2600 2400 2200 2000 1800>,
			<1600 1400 1200 1000 900 800>,
			<700 600 500 400 300 200>,
			<100 0>;
		qcom,lut-data = <5532 5340 5131 5013 4982 4976>,
			<5551 5362 5144 5014 4983 4977>,
			<5567 5379 5152 5014 4984 4979>,
			<5580 5391 5156 5015 4985 4980>,
			<5588 5399 5158 5015 4986 4980>,
			<5591 5401 5158 5016 4987 4981>,
			<5587 5398 5155 5016 4988 4982>,
			<5581 5390 5150 5017 4988 4982>,
			<5575 5383 5147 5017 4989 4983>,
			<5570 5376 5145 5018 4990 4983>,
			<5568 5372 5144 5019 4991 4984>,
			<5571 5370 5144 5021 4992 4985>,
			<5577 5369 5144 5023 4993 4986>,
			<5578 5370 5144 5025 4995 4987>,
			<5575 5375 5146 5028 4997 4988>,
			<5569 5380 5150 5031 4999 4989>,
			<5560 5379 5157 5035 5002 4991>,
			<5545 5376 5166 5040 5004 4994>,
			<5530 5369 5167 5046 5008 4998>,
			<5513 5342 5153 5053 5017 5004>,
			<5498 5311 5137 5057 5022 5009>,
			<5491 5296 5122 5044 5012 5001>,
			<5486 5284 5108 5021 4996 4987>,
			<5481 5277 5101 5013 4988 4981>,
			<5477 5272 5097 5009 4985 4979>,
			<5473 5267 5095 5008 4984 4978>,
			<5467 5261 5095 5008 4984 4978>,
			<5461 5255 5096 5010 4985 4979>,
			<5460 5251 5096 5011 4986 4980>,
			<5469 5250 5097 5013 4988 4981>,
			<5484 5250 5098 5016 4991 4983>,
			<5500 5256 5098 5018 4994 4986>,
			<5521 5275 5096 5019 4997 4989>,
			<5544 5297 5095 5021 4998 4990>,
			<5571 5324 5095 5023 4998 4990>,
			<5601 5356 5096 5024 4997 4990>,
			<5633 5391 5100 5019 4994 4988>,
			<5669 5430 5109 5013 4989 4984>,
			<5706 5470 5119 5011 4988 4983>,
			<5743 5513 5128 5012 4988 4985>,
			<5781 5558 5139 5013 4989 4987>,
			<5822 5607 5152 5015 4990 4987>,
			<5867 5661 5169 5017 4991 4986>,
			<5923 5729 5188 5016 4986 4979>,
			<5996 5816 5215 5019 4985 4978>,
			<6082 5920 5239 5025 4998 4996>,
			<6079 5904 5231 5033 5008 5006>,
			<6149 5976 5259 5043 5019 5017>,
			<6240 6042 5289 5053 5022 5014>,
			<6360 6121 5313 5044 5001 4994>,
			<6544 6202 5329 5033 4995 4989>,
			<6950 6325 5369 5038 4997 4991>,
			<8464 6544 5473 5050 5003 4996>,
			<12069 7113 5666 5073 5019 5016>,
			<12069 7113 5666 5073 5019 5016>,
			<12069 7113 5666 5073 5019 5016>;
	};

};
